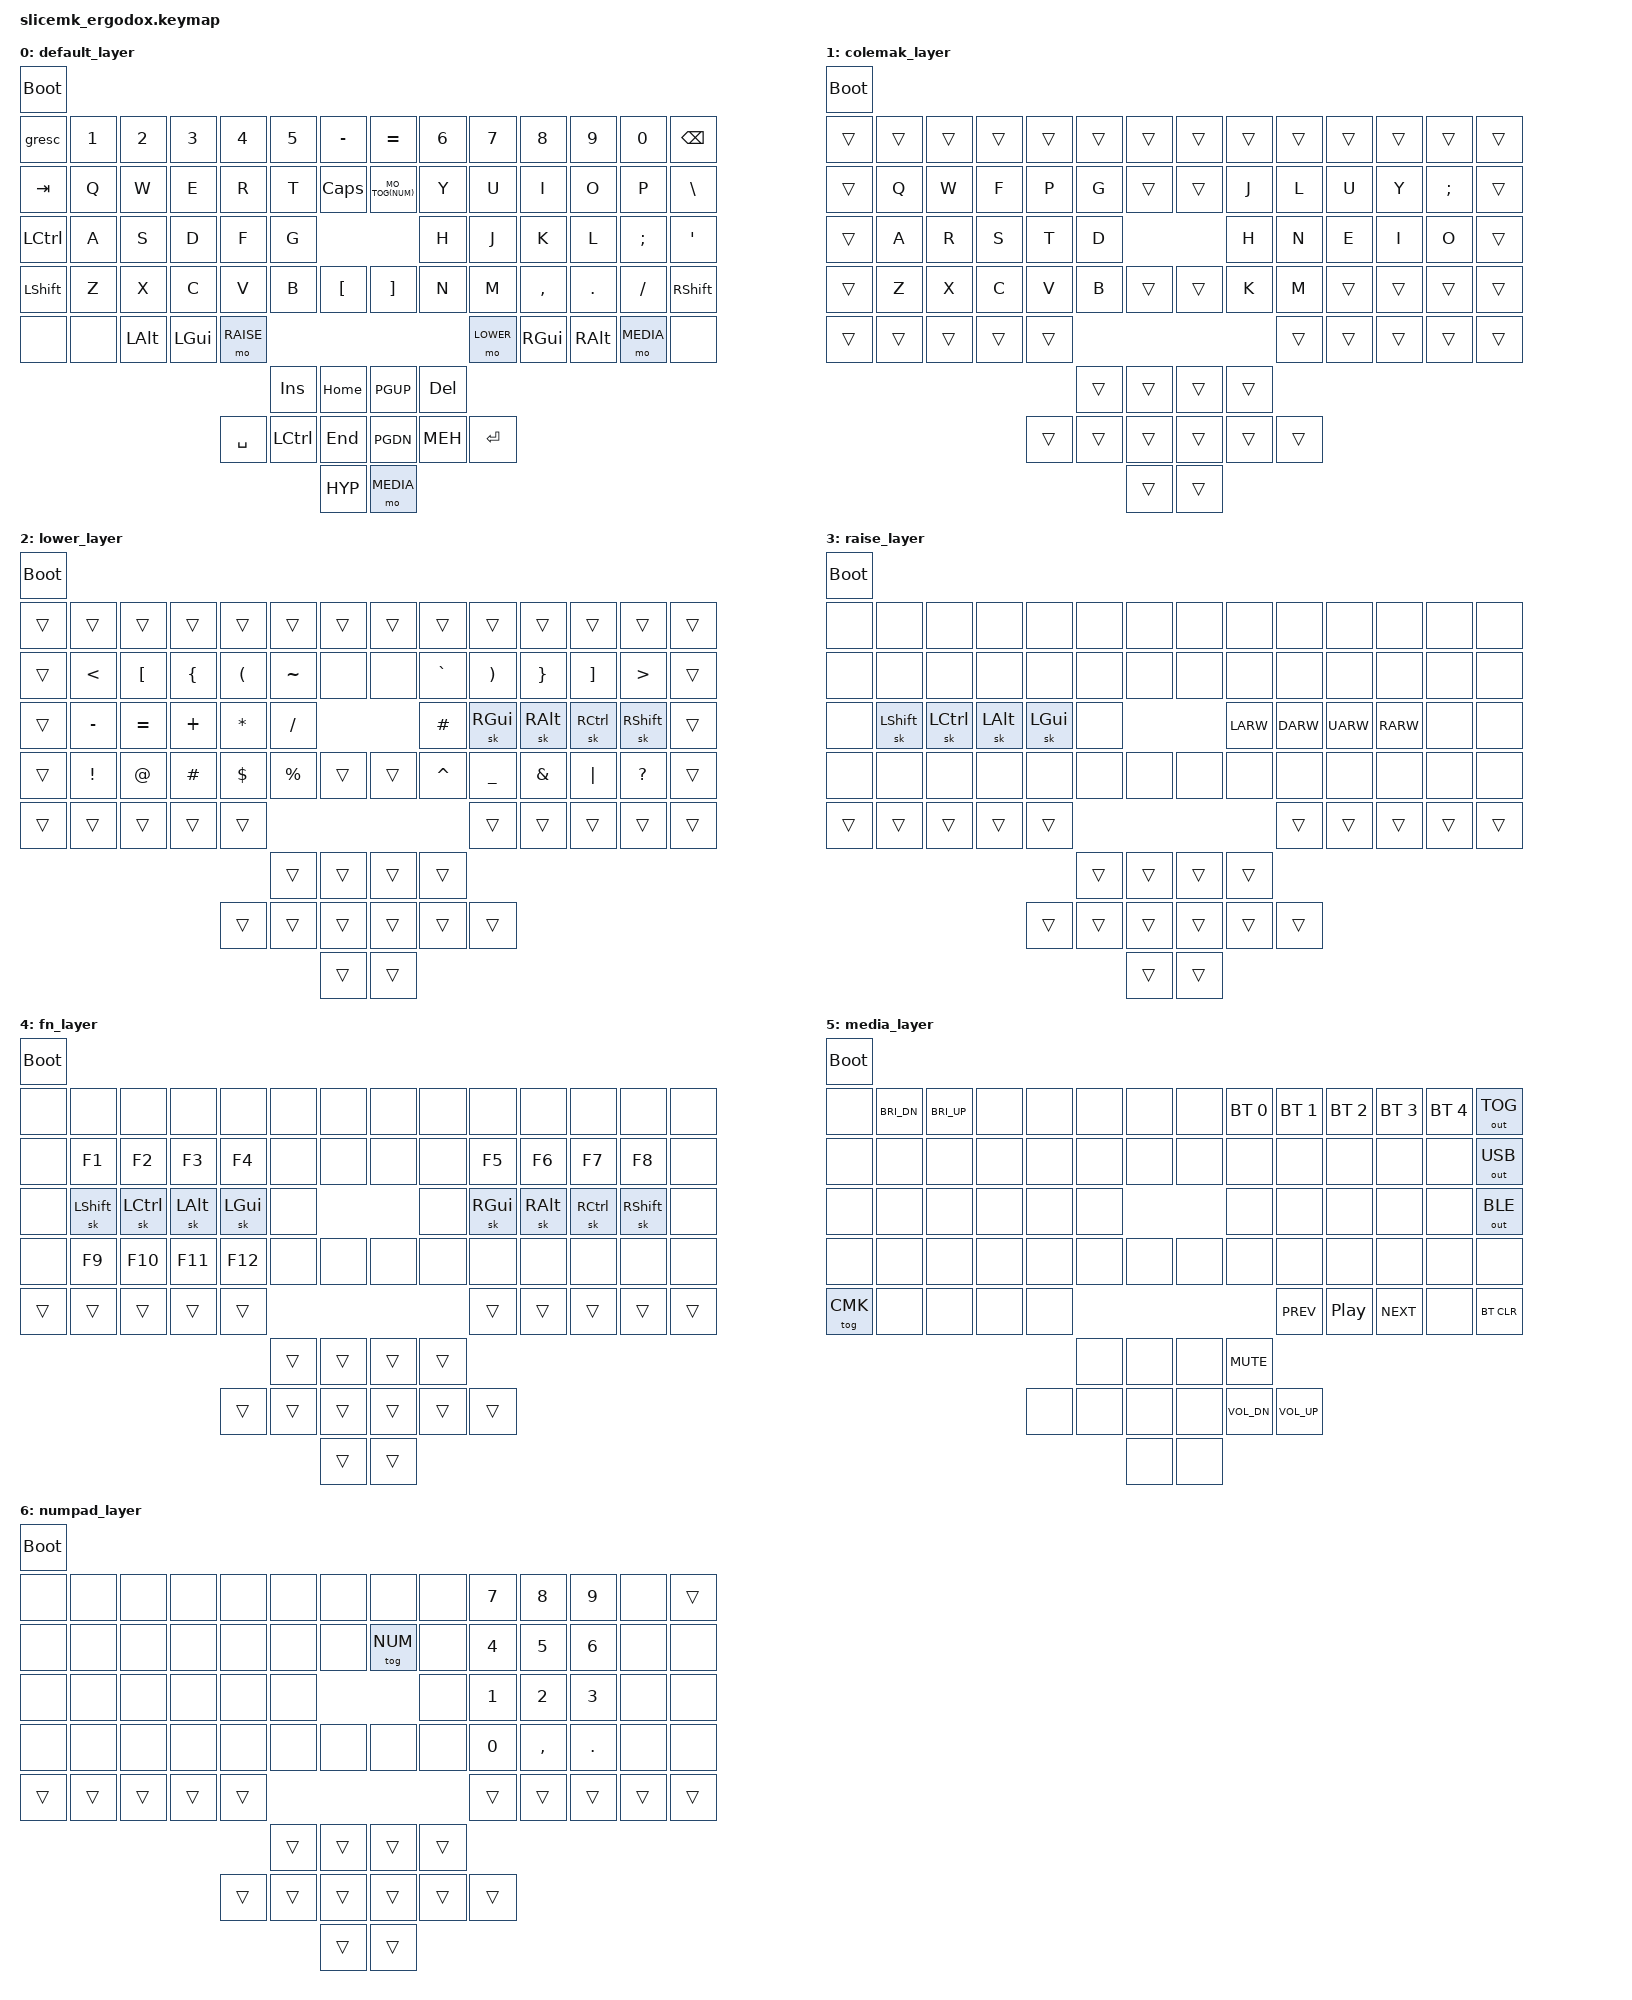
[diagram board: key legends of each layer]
#include <behaviors.dtsi>
#include <dt-bindings/zmk/bt.h>
#include <dt-bindings/zmk/keys.h>
#include <dt-bindings/zmk/outputs.h>

#define DEF 0
#define CMK 1
#define LOWER 2
#define RAISE 3
#define FN 4
#define MEDIA 5
#define NUM 6

#define HYP LS(LC(LA(LGUI)))
#define MEH LC(LA(LGUI))
#define HYPER(key) LS(LC(LA(LG(key))))
#define MO_TOG(layer) &mo_tog layer layer

&mt {
   tapping-term-ms = <200>;
};

/ {
        behaviors {
            mo_tog: behavior_mo_tog {
                compatible = "zmk,behavior-hold-tap";
                label = "mo_tog";
                #binding-cells = <2>;
                flavor = "hold-preferred";
                tapping-term-ms = <200>;
                bindings = <&mo>, <&tog>;
            };
        };

        conditional_layers {
          compatible = "zmk,conditional-layers";
          tri_layer { 
            if-layers = <LOWER RAISE>;
            then-layer = <FN>;
          };
        };

        keymap {
                compatible = "zmk,keymap";

                default_layer {
                        bindings = <
    &bootloader
    &gresc       &kp N1     &kp N2     &kp N3     &kp N4     &kp N5     &kp MINUS  &kp EQUAL   &kp N6    &kp N7    &kp N8     &kp N9     &kp N0     &kp BSPC
    &kp TAB      &kp Q      &kp W      &kp E      &kp R      &kp T      &kp CAPS   MO_TOG(NUM) &kp Y     &kp U     &kp I      &kp O      &kp P      &kp BSLH
    &kp LCTRL    &kp A      &kp S      &kp D      &kp F      &kp G                             &kp H     &kp J     &kp K      &kp L      &kp SEMI   &kp SQT
    &kp LSHFT    &kp Z      &kp X      &kp C      &kp V      &kp B      &kp LBKT   &kp RBKT    &kp N     &kp M     &kp COMMA  &kp DOT    &kp FSLH   &kp RSHFT
    &none        &none      &kp LALT   &kp LGUI   &mo RAISE                                              &mo LOWER &kp RGUI   &kp RALT   &mo MEDIA  &none
                                                             &kp INS    &kp HOME   &kp PGUP    &kp DEL
                                                  &kp SPACE  &kp LCTRL  &kp END    &kp PGDN    &kp MEH   &kp RET
                                                                        &kp HYP    &mo MEDIA
                        >;
                };

                colemak_layer {
                        bindings = <
    &bootloader
    &trans       &trans     &trans     &trans     &trans     &trans     &trans     &trans     &trans    &trans    &trans     &trans     &trans     &trans
    &trans       &kp Q      &kp W      &kp F      &kp P      &kp G      &trans     &trans     &kp J     &kp L     &kp U      &kp Y      &kp SEMI   &trans
    &trans       &kp A      &kp R      &kp S      &kp T      &kp D                            &kp H     &kp N     &kp E      &kp I      &kp O      &trans
    &trans       &kp Z      &kp X      &kp C      &kp V      &kp B      &trans     &trans     &kp K     &kp M     &trans     &trans     &trans     &trans
    &trans       &trans     &trans     &trans     &trans                                                &trans    &trans     &trans     &trans     &trans
                                                             &trans     &trans     &trans     &trans
                                                  &trans     &trans     &trans     &trans     &trans  &trans
                                                                        &trans     &trans
                        >;
                };

                lower_layer {
                        bindings = <
    &bootloader
    &trans     &trans     &trans     &trans     &trans     &trans     &trans     &trans     &trans     &trans     &trans     &trans     &trans     &trans
    &trans     &kp LT     &kp LBKT   &kp LBRC   &kp LPAR   &kp TILDE  &none      &none      &kp GRAVE  &kp RPAR   &kp RBRC   &kp RBKT   &kp GT     &trans
    &trans     &kp MINUS  &kp EQUAL  &kp PLUS   &kp STAR   &kp FSLH                         &kp POUND  &sk RGUI   &sk RALT   &sk RCTRL  &sk RSHFT  &trans
    &trans     &kp EXCL   &kp AT     &kp POUND  &kp DLLR   &kp PRCNT  &trans     &trans     &kp CARET  &kp UNDER  &kp AMPS   &kp PIPE   &kp QMARK  &trans
    &trans     &trans     &trans     &trans     &trans                                                 &trans     &trans     &trans     &trans     &trans
                                                           &trans     &trans     &trans     &trans
                                                                      &trans     &trans
                                                &trans     &trans                           &trans     &trans
                                                                      &trans     &trans
                        >;
                };

                raise_layer {
                        bindings = <
    &bootloader
    &none      &none      &none      &none      &none      &none      &none      &none      &none      &none      &none      &none      &none   &none
    &none      &none      &none      &none      &none      &none      &none      &none      &none      &none      &none      &none      &none   &none
    &none      &sk LSHFT  &sk LCTRL  &sk LALT   &sk LGUI   &none                            &kp LARW   &kp DARW   &kp UARW   &kp RARW   &none   &none 
    &none      &none      &none      &none      &none      &none      &none      &none      &none      &none      &none      &none      &none   &none
    &trans     &trans     &trans     &trans     &trans                                                 &trans     &trans     &trans     &trans  &trans
                                                           &trans     &trans     &trans     &trans
                                                                      &trans     &trans
                                                &trans     &trans                           &trans     &trans
                                                                      &trans     &trans
                        >;
                };

                fn_layer {
                        bindings = <
    &bootloader
    &none      &none      &none      &none      &none      &none      &none      &none      &none      &none      &none      &none      &none      &none
    &none      &kp F1     &kp F2     &kp F3     &kp F4     &none      &none      &none      &none      &kp F5     &kp F6     &kp F7     &kp F8     &none
    &none      &sk LSHFT  &sk LCTRL  &sk LALT   &sk LGUI   &none                            &none      &sk RGUI   &sk RALT   &sk RCTRL  &sk RSHFT  &none 
    &none      &kp F9     &kp F10    &kp F11    &kp F12    &none      &none      &none      &none      &none      &none      &none      &none      &none
    &trans     &trans     &trans     &trans     &trans                                                 &trans     &trans     &trans     &trans     &trans
                                                           &trans     &trans     &trans     &trans
                                                                      &trans     &trans
                                                &trans     &trans                           &trans     &trans
                                                                      &trans     &trans
                        >;
                };

                media_layer {
                        bindings = <
    &bootloader
    &none      &kp C_BRI_DN  &kp C_BRI_UP  &none      &none      &none      &none      &none      &bt BT_SEL 0  &bt BT_SEL 1  &bt BT_SEL 2  &bt BT_SEL 3  &bt BT_SEL 4  &out OUT_TOG
    &none      &none         &none         &none      &none      &none      &none      &none      &none         &none         &none         &none         &none         &out OUT_USB
    &none      &none         &none         &none      &none      &none                            &none         &none         &none         &none         &none         &out OUT_BLE
    &none      &none         &none         &none      &none      &none      &none      &none      &none         &none         &none         &none         &none         &none
    &tog CMK   &none         &none         &none      &none                                                     &kp C_PREV    &kp C_PP      &kp C_NEXT    &none         &bt BT_CLR
                                                                 &none      &none      &none      &kp C_MUTE
                                                      &none      &none      &none      &none      &kp C_VOL_DN  &kp C_VOL_UP
                                                                            &none      &none
                        >;
                };

                numpad_layer {
                        bindings = <
    &bootloader
    &none      &none      &none      &none      &none      &none      &none      &none      &none      &kp N7     &kp N8     &kp N9     &none      &trans
    &none      &none      &none      &none      &none      &none      &none      &tog NUM   &none      &kp N4     &kp N5     &kp N6     &none      &none
    &none      &none      &none      &none      &none      &none                            &none      &kp N1     &kp N2     &kp N3     &none      &none
    &none      &none      &none      &none      &none      &none      &none      &none      &none      &kp N0     &kp COMMA  &kp DOT    &none      &none
    &trans     &trans     &trans     &trans     &trans                                                 &trans     &trans     &trans     &trans     &trans
                                                           &trans     &trans     &trans     &trans
                                                &trans     &trans     &trans     &trans     &trans     &trans
                                                                      &trans     &trans
                        >;
                };
        };
};
